# AT32F413xx_v2 register map
Vendor: Keil; Series: AT32F413; File version: 1.0
CPU: CM4 r0p1, little endian, no MPU, FPU, 4 interrupt priority bits
Registers are 32-bit, read-write, reset 0x0 unless marked. A register's access mark holds for its fields unless they carry their own. Offsets are from the block's base; [hi:lo] are bit positions; {n}, {i} and the like mark numbered series.

## EXINT
Base 0x40010400
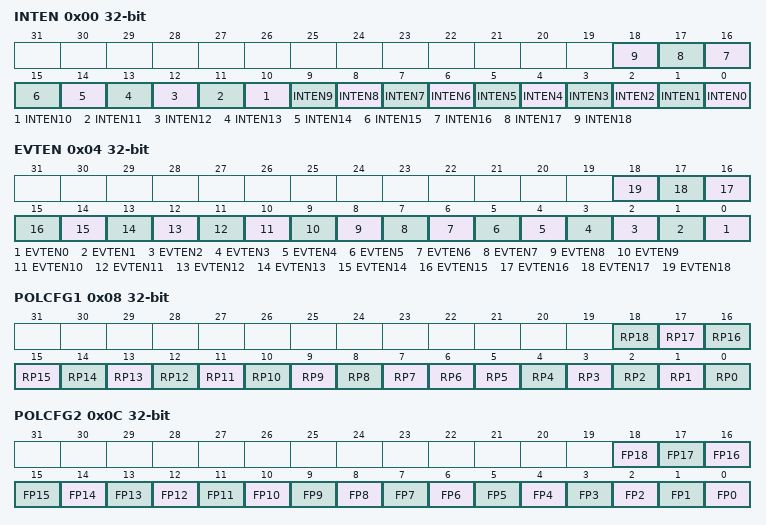
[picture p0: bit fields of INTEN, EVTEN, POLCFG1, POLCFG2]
0x00 INTEN — Interrupt enable register
  [n] INTEN{n} (n=0..18) — Interrupt enable or disable on line {n}
0x04 EVTEN — Event enable register
  [n] EVTEN{n} (n=0..18) — Event enable or disable on line {n}
0x08 POLCFG1 — Rising polarity configuration register
  [n] RP{n} (n=7..18) — Rising polarity configuration bit of line {n}
  [6] RP6 — Rising polarity configuration bit of linee 6
  [n] RP{n} (n=0..5) — Rising polarity configuration bit of line {n}
0x0C POLCFG2 — Falling polarity configuration register
  [n] FP{n} (n=0..18) — Falling polarity event configuration bit of line {n}
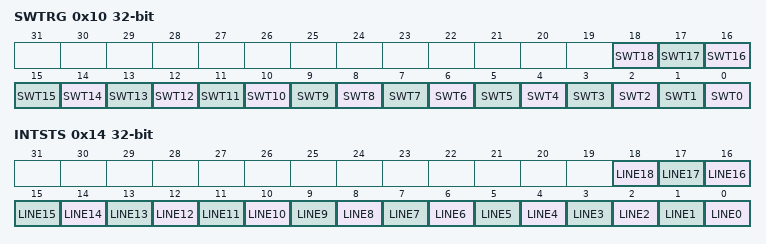
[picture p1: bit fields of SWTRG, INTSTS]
0x10 SWTRG — Software triggle register
  [n] SWT{n} (n=0..18) — Software triggle on line {n}
0x14 INTSTS — Interrupt status register
  [n] LINE{n} (n=0..18) — Line {n} state bit

## RTC — Real time clock
Base 0x40002800
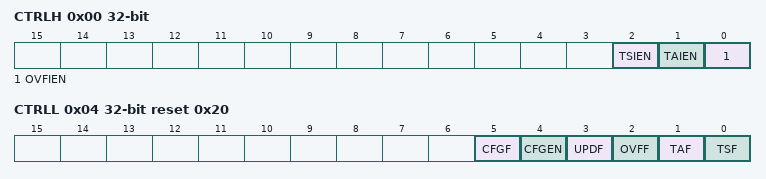
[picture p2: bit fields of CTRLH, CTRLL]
0x00 CTRLH — RTC Control Register High
  [2] TSIEN — Time second interrupt enable
  [1] TAIEN — Time alarm interrupt enable
  [0] OVFIEN — Overflow interrupt enable
0x04 CTRLL reset 0x20 — RTC Control Register Low
  [5] CFGF ro — RTC configuration finish
  [4] CFGEN — RTC configuration enable
  [3] UPDF — RTC update finish
  [2] OVFF — Overflow Flag
  [1] TAF — Time alarm flag
  [0] TSF — Time second flag
0x08 DIVH wo — RTC Divider Register High
  [3:0] DIV — RTC divider high
0x0C DIVL wo reset 0x8000 — RTC Divider Register Low
  [15:0] DIV — RTC divider low
0x10 DIVCNTH — RTC Divider Register High
  [3:0] DIVCNT — RTC divider register high
0x14 DIVCNTL reset 0x8000 — RTC Divider Register Low
  [15:0] DIVCNT — RTC divider register low
0x18 CNTH — RTC Counter Register High
  [15:0] CNT — RTC counter register high
0x1C CNTL — RTC Counter Register Low
  [15:0] CNT — RTC counter register low
0x20 TAH wo reset 0xFFFF — RTC Alarm Register High
  [15:0] TA — Time alarm register high
0x24 TAL wo reset 0xFFFF — Time alarm register low
  [15:0] TA — RTC alarm register low

## BPR — Battery powered register
Base 0x40006C04
0x00 DT1 — Battery powered domain data register (BPR_DTx)
  [15:0] DT1 — BPR data1
0x04 DT2 — Battery powered domain data register (BPR_DTx)
  [15:0] DT2 — BPR data2
0x08 DT3 — Battery powered domain data register (BPR_DTx)
  [15:0] DT3 — BPR data3
0x0C DT4 — Battery powered domain data register (BPR_DTx)
  [15:0] DT4 — BPR data4
0x10 DT5 — Battery powered domain data register (BPR_DTx)
  [15:0] DT5 — BPR data5
0x14 DT6 — Battery powered domain data register (BPR_DTx)
  [15:0] DT6 — BPR data6
0x18 DT7 — Battery powered domain data register (BPR_DTx)
  [15:0] DT7 — BPR data7
0x1C DT8 — Battery powered domain data register (BPR_DTx)
  [15:0] DT8 — BPR data8
0x20 DT9 — Battery powered domain data register (BPR_DTx)
  [15:0] DT9 — BPR data9
0x24 DT10 — Battery powered domain data register (BPR_DTx)
  [15:0] DT10 — BPR data10
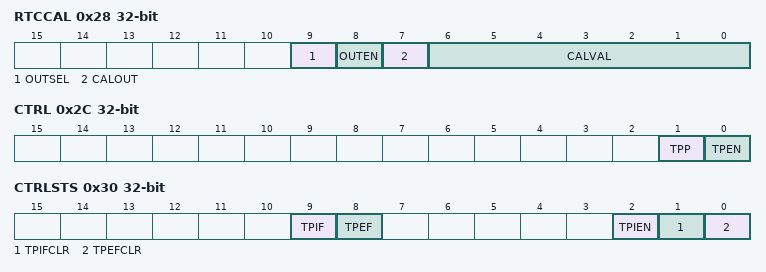
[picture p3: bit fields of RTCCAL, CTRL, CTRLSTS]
0x28 RTCCAL — RTC clock calibration register (BPR_RTCCAL)
  [9] OUTSEL — Output selection
  [8] OUTEN — Output enable
  [7] CALOUT — Calibration Clock Output
  [6:0] CALVAL — Calibration value
0x2C CTRL — BPR control register (BPR_CTRL)
  [1] TPP — TAMPER pin polarity
  [0] TPEN — Tamper pin enable
0x30 CTRLSTS — BPR control/status register (BPR_CTRLSTS)
  [9] TPIF — Tamper interrupt flag
  [8] TPEF — Tamper event flag
  [2] TPIEN — Tamper pin interrupt enable
  [1] TPIFCLR wo — Tamper interrupt flag clear
  [0] TPEFCLR wo — Tamper event flag clear
{0x10+4i} DT{i} (i=11..42) — Battery powered domain data register (BPR_DTx)
  [15:0] DT{i} — BPR data{i}

## WDT — Watchdog
Base 0x40003000
0x00 CMD — Command register
  [15:0] CMD
0x04 DIV — Division register
  [2:0] DIV — Division divider
0x08 RLD reset 0xFFF — Reload register
  [11:0] RLD — Reload value
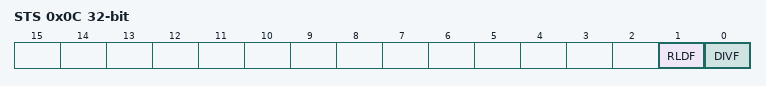
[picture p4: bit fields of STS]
0x0C STS — Status register
  [1] RLDF — Reload value update complete flag
  [0] DIVF — Division value update complete flag

## Notices in the file
Copyright (C) 2012-2014 ARM Limited. All rights reserved.
Purpose: System Viewer Description (SVD) Example (Schema Version 1.1)
This is a description of a none-existent and incomplete device
for demonstration purposes only.
Redistribution and use in source and binary forms, with or without
modification, are permitted provided that the following conditions are met:
- Redistributions of source code must retain the above copyright
notice, this list of conditions and the following disclaimer.
- Redistributions in binary form must reproduce the above copyright
notice, this list of conditions and the following disclaimer in the
documentation and/or other materials provided with the distribution.
- Neither the name of ARM nor the names of its contributors may be used
to endorse or promote products derived from this software without
specific prior written permission.
THIS SOFTWARE IS PROVIDED BY THE COPYRIGHT HOLDERS AND CONTRIBUTORS "AS IS"
AND ANY EXPRESS OR IMPLIED WARRANTIES, INCLUDING, BUT NOT LIMITED TO, THE
IMPLIED WARRANTIES OF MERCHANTABILITY AND FITNESS FOR A PARTICULAR PURPOSE
ARE DISCLAIMED. IN NO EVENT SHALL COPYRIGHT HOLDERS AND CONTRIBUTORS BE
LIABLE FOR ANY DIRECT, INDIRECT, INCIDENTAL, SPECIAL, EXEMPLARY, OR
CONSEQUENTIAL DAMAGES (INCLUDING, BUT NOT LIMITED TO, PROCUREMENT OF
SUBSTITUTE GOODS OR SERVICES; LOSS OF USE, DATA, OR PROFITS; OR BUSINESS
INTERRUPTION) HOWEVER CAUSED AND ON ANY THEORY OF LIABILITY, WHETHER IN
CONTRACT, STRICT LIABILITY, OR TORT (INCLUDING NEGLIGENCE OR OTHERWISE)
ARISING IN ANY WAY OUT OF THE USE OF THIS SOFTWARE, EVEN IF ADVISED OF THE
POSSIBILITY OF SUCH DAMAGE.
